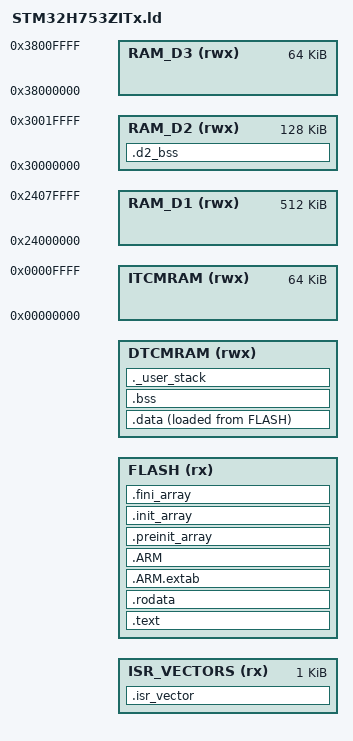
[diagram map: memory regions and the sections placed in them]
/*
******************************************************************************
**
**  File        : LinkerScript.ld
**
**  Author      : Auto-generated by STM32CubeIDE
**
**  Abstract    : Linker script for NUCLEO-H753ZI Board embedding STM32H753ZITx Device from STM32H7 series
**                      2048Kbytes FLASH
**                      128Kbytes DTCMRAM
**                      512Kbytes RAM_D1
**                      64Kbytes RAM_D3
**                      64Kbytes ITCMRAM
**                      128Kbytes RAM_D2
**
**                Set stack size and stack location according
**                to application requirements.
**
**                Set memory bank area and size if external memory is used.
**
**  Target      : STMicroelectronics STM32
**
**  Distribution: The file is distributed as is without any warranty
**                of any kind.
**
*****************************************************************************
** @attention
**
** <h2><center>&copy; COPYRIGHT(c) 2019 STMicroelectronics</center></h2>
**
** Redistribution and use in source and binary forms, with or without modification,
** are permitted provided that the following conditions are met:
**   1. Redistributions of source code must retain the above copyright notice,
**      this list of conditions and the following disclaimer.
**   2. Redistributions in binary form must reproduce the above copyright notice,
**      this list of conditions and the following disclaimer in the documentation
**      and/or other materials provided with the distribution.
**   3. Neither the name of STMicroelectronics nor the names of its contributors
**      may be used to endorse or promote products derived from this software
**      without specific prior written permission.
**
** THIS SOFTWARE IS PROVIDED BY THE COPYRIGHT HOLDERS AND CONTRIBUTORS "AS IS"
** AND ANY EXPRESS OR IMPLIED WARRANTIES, INCLUDING, BUT NOT LIMITED TO, THE
** IMPLIED WARRANTIES OF MERCHANTABILITY AND FITNESS FOR A PARTICULAR PURPOSE ARE
** DISCLAIMED. IN NO EVENT SHALL THE COPYRIGHT HOLDER OR CONTRIBUTORS BE LIABLE
** FOR ANY DIRECT, INDIRECT, INCIDENTAL, SPECIAL, EXEMPLARY, OR CONSEQUENTIAL
** DAMAGES (INCLUDING, BUT NOT LIMITED TO, PROCUREMENT OF SUBSTITUTE GOODS OR
** SERVICES; LOSS OF USE, DATA, OR PROFITS; OR BUSINESS INTERRUPTION) HOWEVER
** CAUSED AND ON ANY THEORY OF LIABILITY, WHETHER IN CONTRACT, STRICT LIABILITY,
** OR TORT (INCLUDING NEGLIGENCE OR OTHERWISE) ARISING IN ANY WAY OUT OF THE USE
** OF THIS SOFTWARE, EVEN IF ADVISED OF THE POSSIBILITY OF SUCH DAMAGE.
**
*****************************************************************************
*/
/*
 * Copyright (c) 2020 Microsoft. All rights reserved.
 */

/*
 * Note: This file needs to be included by a per-image linkerscript.
 */

/* Entry Point */
ENTRY(Reset_Handler)

VECTOR_SIZE = 0x400;

/* Specific ROM/RAM definitions */
__INTVECT_START__ = __IMAGE_START__;
__ROM_START__     = __INTVECT_START__ + VECTOR_SIZE;
__ROM_LENGTH__    = __IMAGE_END__ - __ROM_START__ + 1;

__RAM_START__     = __DTCM_START__;
__RAM_END__       = __DTCM_END__;
__RAM_LENGTH__    = __RAM_END__ - __RAM_START__ + 1;

/* Highest address of the user mode stack */
_estack = __RAM_END__ + 1;

_Min_Stack_Size = 0xC000; /* required amount of stack */

/* Memories definition */
MEMORY
{
    ISR_VECTORS (rx)  : ORIGIN = __INTVECT_START__, LENGTH = VECTOR_SIZE
    FLASH       (rx)  : ORIGIN = __ROM_START__, LENGTH = __ROM_LENGTH__
    DTCMRAM     (rwx) : ORIGIN = __RAM_START__, LENGTH = __RAM_LENGTH__
    RAM_D1      (rwx) : ORIGIN = 0x24000000, LENGTH = 512K
    RAM_D3      (rwx) : ORIGIN = 0x38000000, LENGTH = 64K
    ITCMRAM     (rwx) : ORIGIN = 0x00000000, LENGTH = 64K
    RAM_D2      (rwx) : ORIGIN = 0x30000000, LENGTH = 128K
}

/* Sections */
SECTIONS
{
  /* The startup code into "FLASH" Rom type memory */
  .isr_vector :
  {
    . = ALIGN(4);
    KEEP(*(.isr_vector)) /* Startup code */
    . = ALIGN(4);
  } >ISR_VECTORS

  /* The program code and other data into "FLASH" Rom type memory */
  .text :
  {
    . = ALIGN(4);
    *(.text)           /* .text sections (code) */
    *(.text*)          /* .text* sections (code) */
    *(.glue_7)         /* glue arm to thumb code */
    *(.glue_7t)        /* glue thumb to arm code */
    *(.eh_frame)

    KEEP (*(.init))
    KEEP (*(.fini))

    . = ALIGN(4);
    _etext = .;        /* define a global symbols at end of code */
  } >FLASH

  /* Constant data into "FLASH" Rom type memory */
  .rodata :
  {
    . = ALIGN(4);
    *(.rodata)         /* .rodata sections (constants, strings, etc.) */
    *(.rodata*)        /* .rodata* sections (constants, strings, etc.) */
    . = ALIGN(4);
  } >FLASH

  .ARM.extab   : {
    . = ALIGN(4);
    *(.ARM.extab* .gnu.linkonce.armextab.*)
    . = ALIGN(4);
  } >FLASH

  .ARM : {
    . = ALIGN(4);
    __exidx_start = .;
    *(.ARM.exidx*)
    __exidx_end = .;
    . = ALIGN(4);
  } >FLASH

  .preinit_array     :
  {
    . = ALIGN(4);
    PROVIDE_HIDDEN (__preinit_array_start = .);
    KEEP (*(.preinit_array*))
    PROVIDE_HIDDEN (__preinit_array_end = .);
    . = ALIGN(4);
  } >FLASH

  .init_array :
  {
    . = ALIGN(4);
    PROVIDE_HIDDEN (__init_array_start = .);
    KEEP (*(SORT(.init_array.*)))
    KEEP (*(.init_array*))
    PROVIDE_HIDDEN (__init_array_end = .);
    . = ALIGN(4);
  } >FLASH

  .fini_array :
  {
    . = ALIGN(4);
    PROVIDE_HIDDEN (__fini_array_start = .);
    KEEP (*(SORT(.fini_array.*)))
    KEEP (*(.fini_array*))
    PROVIDE_HIDDEN (__fini_array_end = .);
    . = ALIGN(4);
  } >FLASH

  /* Used by the startup to initialize data */
  _sidata = LOADADDR(.data);

  /* Initialized data sections into "DTCM" Ram type memory */
  .data :
  {
    . = ALIGN(4);
    _sdata = .;        /* create a global symbol at data start */
    *(.data)           /* .data sections */
    *(.data*)          /* .data* sections */

    . = ALIGN(4);
    _edata = .;        /* define a global symbol at data end */

  } >DTCMRAM AT> FLASH

  /* Uninitialized data section into "DTCM" Ram type memory */
  . = ALIGN(4);
  .bss (NOLOAD) :
  {
    /* This is used by the startup in order to initialize the .bss secion */
    _sbss = .;         /* define a global symbol at bss start */
    __bss_start__ = _sbss;
    *(.bss)
    *(.bss*)
    *(COMMON)

    . = ALIGN(4);
    _ebss = .;         /* define a global symbol at bss end */
    __bss_end__ = _ebss;
  } >DTCMRAM

  /* User_stack section, used to check that there is enough "DTCM" Ram type memory left */
  ._user_stack (NOLOAD) :
  {
    . = ALIGN(8);
    PROVIDE ( end = . );
    PROVIDE ( _end = . );
    . = . + _Min_Stack_Size;
    . = ALIGN(8);
  } >DTCMRAM

  /* Uninitialized data section into "RAM_D2" Ram type memory */
  .d2_bss (NOLOAD) :
  {
    *(.d2_bss*)
  } >RAM_D2

  /* Remove information from the compiler libraries */
  /DISCARD/ :
  {
    libc.a ( * )
    libm.a ( * )
    libgcc.a ( * )
  }

  .ARM.attributes 0 : { *(.ARM.attributes) }
}
